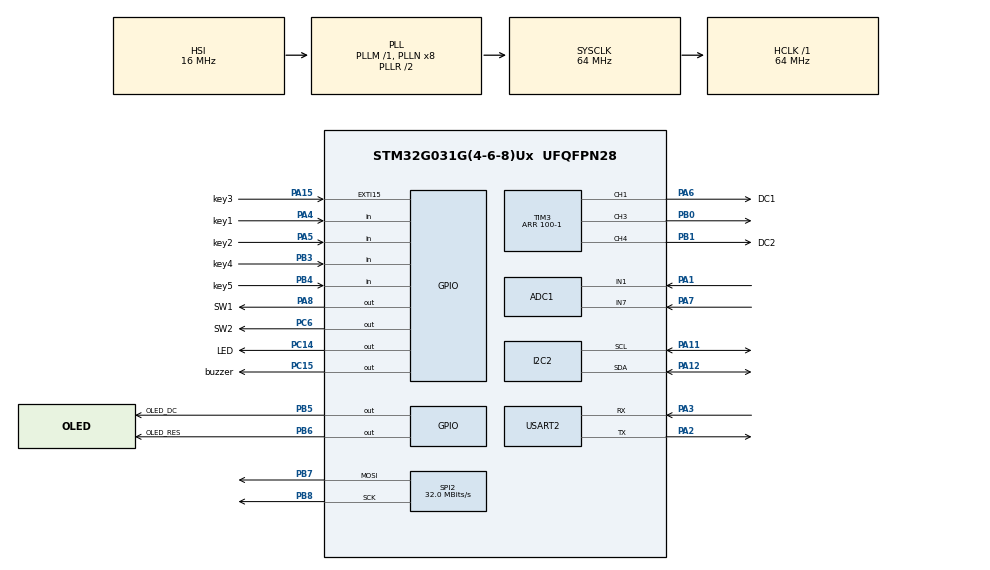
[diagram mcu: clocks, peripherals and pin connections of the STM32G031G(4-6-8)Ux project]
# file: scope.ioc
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ADC1.Channel-0\#ChannelRegularConversion=ADC_CHANNEL_1
ADC1.Channel-3\#ChannelRegularConversion=ADC_CHANNEL_7
ADC1.Channel-4\#ChannelRegularConversion=ADC_CHANNEL_VREFINT
ADC1.ClockPrescaler=ADC_CLOCK_SYNC_PCLK_DIV2
ADC1.ContinuousConvMode=DISABLE
ADC1.DMAContinuousRequests=ENABLE
ADC1.EOCSelection=ADC_EOC_SEQ_CONV
ADC1.ExternalTrigConv=ADC_EXTERNALTRIG_T2_TRGO
ADC1.NbrOfConversion=3
ADC1.NbrOfConversionFlag=1
ADC1.Overrun=ADC_OVR_DATA_OVERWRITTEN
ADC1.Rank-3\#ChannelRegularConversion=2
ADC1.Rank-4\#ChannelRegularConversion=3
ADC1.SamplingTime-3\#ChannelRegularConversion=ADC_SAMPLINGTIME_COMMON_1
ADC1.SamplingTime-4\#ChannelRegularConversion=ADC_SAMPLINGTIME_COMMON_2
ADC1.SamplingTimeCommon1=ADC_SAMPLETIME_1CYCLE_5
ADC1.SamplingTimeCommon2=ADC_SAMPLETIME_1CYCLE_5
ADC1.SelectedChannel=ADC_CHANNEL_1|ADC_CHANNEL_7|ADC_CHANNEL_VREFINT
ADC1.master=1
Dma.ADC1.2.Direction=DMA_PERIPH_TO_MEMORY
Dma.ADC1.2.EventEnable=DISABLE
Dma.ADC1.2.Instance=DMA1_Channel1
Dma.ADC1.2.MemDataAlignment=DMA_MDATAALIGN_HALFWORD
Dma.ADC1.2.MemInc=DMA_MINC_ENABLE
Dma.ADC1.2.Mode=DMA_CIRCULAR
Dma.ADC1.2.PeriphDataAlignment=DMA_PDATAALIGN_HALFWORD
Dma.ADC1.2.PeriphInc=DMA_PINC_DISABLE
Dma.ADC1.2.Polarity=HAL_DMAMUX_REQ_GEN_RISING
Dma.ADC1.2.Priority=DMA_PRIORITY_LOW
Dma.ADC1.2.RequestNumber=1
Dma.ADC1.2.SignalID=NONE
Dma.ADC1.2.SyncEnable=DISABLE
Dma.ADC1.2.SyncPolarity=HAL_DMAMUX_SYNC_NO_EVENT
Dma.ADC1.2.SyncRequestNumber=1
Dma.ADC1.2.SyncSignalID=NONE
Dma.Request0=USART2_RX
Dma.Request1=USART2_TX
Dma.Request2=ADC1
Dma.USART2_RX.0.Direction=DMA_PERIPH_TO_MEMORY
Dma.USART2_RX.0.EventEnable=DISABLE
Dma.USART2_RX.0.Instance=DMA1_Channel2
Dma.USART2_RX.0.MemDataAlignment=DMA_MDATAALIGN_BYTE
Dma.USART2_RX.0.MemInc=DMA_MINC_ENABLE
Dma.USART2_RX.0.Mode=DMA_CIRCULAR
Dma.USART2_RX.0.PeriphDataAlignment=DMA_PDATAALIGN_BYTE
Dma.USART2_RX.0.PeriphInc=DMA_PINC_DISABLE
Dma.USART2_RX.0.Polarity=HAL_DMAMUX_REQ_GEN_RISING
Dma.USART2_RX.0.Priority=DMA_PRIORITY_LOW
Dma.USART2_RX.0.RequestNumber=1
Dma.USART2_RX.0.SignalID=NONE
Dma.USART2_RX.0.SyncEnable=DISABLE
Dma.USART2_RX.0.SyncPolarity=HAL_DMAMUX_SYNC_NO_EVENT
Dma.USART2_RX.0.SyncRequestNumber=1
Dma.USART2_RX.0.SyncSignalID=NONE
Dma.USART2_TX.1.Direction=DMA_MEMORY_TO_PERIPH
Dma.USART2_TX.1.EventEnable=DISABLE
Dma.USART2_TX.1.Instance=DMA1_Channel3
Dma.USART2_TX.1.MemDataAlignment=DMA_MDATAALIGN_BYTE
Dma.USART2_TX.1.MemInc=DMA_MINC_ENABLE
Dma.USART2_TX.1.Mode=DMA_CIRCULAR
Dma.USART2_TX.1.PeriphDataAlignment=DMA_PDATAALIGN_BYTE
Dma.USART2_TX.1.PeriphInc=DMA_PINC_DISABLE
Dma.USART2_TX.1.Polarity=HAL_DMAMUX_REQ_GEN_RISING
Dma.USART2_TX.1.Priority=DMA_PRIORITY_LOW
Dma.USART2_TX.1.RequestNumber=1
Dma.USART2_TX.1.SignalID=NONE
Dma.USART2_TX.1.SyncEnable=DISABLE
Dma.USART2_TX.1.SyncPolarity=HAL_DMAMUX_SYNC_NO_EVENT
Dma.USART2_TX.1.SyncRequestNumber=1
Dma.USART2_TX.1.SyncSignalID=NONE
I2C2.Timing=0x10B17DB5
Mcu.Family=STM32G0
Mcu.Name=STM32G031G(4-6-8)Ux
Mcu.Package=UFQFPN28
NVIC.ADC1_IRQn=true\:1\:0\:true\:false\:true\:true\:true\:true
NVIC.DMA1_Channel1_IRQn=true\:1\:0\:true\:false\:true\:false\:true\:true
NVIC.DMA1_Channel2_3_IRQn=true\:1\:0\:true\:false\:true\:false\:true\:true
NVIC.EXTI4_15_IRQn=true\:0\:0\:false\:false\:true\:true\:true\:true
NVIC.I2C2_IRQn=true\:1\:0\:true\:false\:true\:true\:true\:true
NVIC.TIM17_IRQn=true\:0\:0\:true\:false\:true\:true\:true\:true
NVIC.TIM3_IRQn=true\:0\:0\:false\:false\:true\:true\:true\:true
PA1.Mode=IN1
PA1.Signal=ADC1_IN1
PA11\ [PA9].Mode=I2C
PA11\ [PA9].Signal=I2C2_SCL
PA12\ [PA10].Mode=I2C
PA12\ [PA10].Signal=I2C2_SDA
PA13.Mode=Serial_Wire
PA13.Signal=SYS_SWDIO
PA14-BOOT0.Mode=Serial_Wire
PA14-BOOT0.Signal=SYS_SWCLK
PA15.GPIO_Label=key3
PA15.GPIO_ModeDefaultEXTI=GPIO_MODE_IT_RISING_FALLING
PA15.Signal=GPXTI15
PA2.Mode=Asynchronous
PA2.Signal=USART2_TX
PA3.Mode=Asynchronous
PA3.Signal=USART2_RX
PA4.GPIO_Label=key1
PA4.Signal=GPIO_Input
PA5.GPIO_Label=key2
PA5.Signal=GPIO_Input
PA6.GPIO_Label=DC1
PA6.Signal=S_TIM3_CH1
PA7.Mode=IN7
PA7.Signal=ADC1_IN7
PA8.GPIO_Label=SW1
PA8.PinState=GPIO_PIN_SET
PA8.Signal=GPIO_Output
PB0.Signal=S_TIM3_CH3
PB1.GPIO_Label=DC2
PB1.Signal=S_TIM3_CH4
PB3.GPIO_Label=key4
PB3.Signal=GPIO_Input
PB4.GPIO_Label=key5
PB4.Signal=GPIO_Input
PB5.GPIO_Label=OLED_DC
PB5.GPIO_Speed=GPIO_SPEED_FREQ_HIGH
PB5.Signal=GPIO_Output
PB6.GPIO_Label=OLED_RES
PB6.GPIO_Speed=GPIO_SPEED_FREQ_HIGH
PB6.PinState=GPIO_PIN_RESET
PB6.Signal=GPIO_Output
PB7.GPIO_FM7=SYSCFG_FASTMODEPLUS_PB7
PB7.GPIO_Speed=GPIO_SPEED_FREQ_HIGH
PB7.Mode=TX_Only_Simplex_Unidirect_Master
PB7.Signal=SPI2_MOSI
PB8.GPIO_FM8=SYSCFG_FASTMODEPLUS_PB8
PB8.GPIO_Speed=GPIO_SPEED_FREQ_HIGH
PB8.Mode=TX_Only_Simplex_Unidirect_Master
PB8.Signal=SPI2_SCK
PC14-OSC32_IN\ (PC14).GPIO_Label=LED
PC14-OSC32_IN\ (PC14).Signal=GPIO_Output
PC15-OSC32_OUT\ (PC15).GPIO_Label=buzzer
PC15-OSC32_OUT\ (PC15).Signal=GPIO_Output
PC6.GPIO_Label=SW2
PC6.PinState=GPIO_PIN_SET
PC6.Signal=GPIO_Output
ProjectManager.HeapSize=0x200
ProjectManager.StackSize=0x400
ProjectManager.TargetToolchain=MDK-ARM V5.32
RCC.ADCFreq_Value=64000000
RCC.AHBFreq_Value=64000000
RCC.CortexFreq_Value=64000000
RCC.EXTERNAL_CLOCK_VALUE=12288000
RCC.HCLKFreq_Value=64000000
RCC.HSE_VALUE=8000000
RCC.HSI_VALUE=16000000
RCC.LSE_VALUE=32768
RCC.PLLQ=RCC_PLLQ_DIV4
RCC.SYSCLKFreq_VALUE=64000000
RCC.SYSCLKSource=RCC_SYSCLKSOURCE_PLLCLK
RCC.VCOOutputFreq_Value=128000000
SH.S_TIM3_CH1.0=TIM3_CH1,PWM Generation1 CH1
SH.S_TIM3_CH3.0=TIM3_CH3,PWM Generation3 CH3
SH.S_TIM3_CH4.0=TIM3_CH4,PWM Generation4 CH4
SPI2.CLKPolarity=SPI_POLARITY_HIGH
SPI2.CalculateBaudRate=32.0 MBits/s
SPI2.Direction=SPI_DIRECTION_2LINES
SPI2.Mode=SPI_MODE_MASTER
SPI2.VirtualType=VM_MASTER
TIM17.AutoReloadPreload=TIM_AUTORELOAD_PRELOAD_ENABLE
TIM17.Period=10-1
TIM17.Prescaler=6400-1
TIM2.AutoReloadPreload=TIM_AUTORELOAD_PRELOAD_ENABLE
TIM2.Channel-Output\ Compare2\ No\ Output=TIM_CHANNEL_2
TIM2.Period=100-1
TIM2.Pulse-Output\ Compare2\ No\ Output=50-1
TIM2.TIM_MasterOutputTrigger=TIM_TRGO_UPDATE
TIM2.TIM_MasterSlaveMode=TIM_MASTERSLAVEMODE_ENABLE
TIM3.AutoReloadPreload=TIM_AUTORELOAD_PRELOAD_DISABLE
TIM3.Channel-PWM\ Generation1\ CH1=TIM_CHANNEL_1
TIM3.Channel-PWM\ Generation3\ CH3=TIM_CHANNEL_3
TIM3.Channel-PWM\ Generation4\ CH4=TIM_CHANNEL_4
TIM3.OCFastMode_PWM-PWM\ Generation1\ CH1=TIM_OCFAST_ENABLE
TIM3.OCFastMode_PWM-PWM\ Generation4\ CH4=TIM_OCFAST_ENABLE
TIM3.Period=100-1
TIM3.Pulse-PWM\ Generation1\ CH1=50
TIM3.Pulse-PWM\ Generation3\ CH3=50
TIM3.Pulse-PWM\ Generation4\ CH4=50
USART2.VirtualMode-Asynchronous=VM_ASYNC
VP_ADC1_Vref_Input.Mode=IN-Vrefint
VP_TIM17_VS_ClockSourceINT.Mode=Enable_Timer
VP_TIM2_VS_ClockSourceINT.Mode=Internal
VP_TIM2_VS_no_output2.Mode=Output Compare2 No Output
VP_TIM3_VS_ClockSourceINT.Mode=Internal
board=custom

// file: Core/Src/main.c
/* USER CODE BEGIN Header */
/**
  ******************************************************************************
  * @file           : main.c
  * @brief          : Main program body
  * @author         : Max-unterwegs
  * @date           : 2025-03-07 20:07:21
  * @note           : scope主函数，完整工程见https://github.com/Max-unterwegs/scope-von-Max_unterwegs
  ******************************************************************************
  * @attention
  *
  * Copyright (c) 2025 STMicroelectronics.
  * All rights reserved.
  *
  * This software is licensed under terms that can be found in the LICENSE file
  * in the root directory of this software component.
  * If no LICENSE file comes with this software, it is provided AS-IS.
  *
  ******************************************************************************
  */
/*
 *                        _oo0oo_
 *                       o8888888o
 *                       88" . "88
 *                       (| -_- |)
 *                       0\  =  /0
 *                     ___/`---'\___
 *                   .' \\|     |// '.
 *                  / \\|||  :  |||// \
 *                 / _||||| -:- |||||- \
 *                |   | \\\  - /// |   |
 *                | \_|  ''\---/''  |_/ |
 *                \  .-\__  '-'  ___/-. /
 *              ___'. .'  /--.--\  `. .'___
 *           ."" '<  `.___\_<|>_/___.' >' "".
 *          | | :  `- \`.;`\ _ /`;.`/ - ` : | |
 *          \  \ `_.   \_ __\ /__ _/   .-` /  /
 *      =====`-.____`.___ \_____/___.-`___.-'=====
 *                        `=---='
 *
 *
 *      ~~~~~~~~~~~~~~~~~~~~~~~~~~~~~~~~~~~~~~~~~~~
 *
 *            佛祖保佑     永不宕机     永无BUG
 */

/* USER CODE END Header */
#include "main.h"
#include "adc.h"
#include "dma.h"
#include "i2c.h"
#include "spi.h"
#include "tim.h"
#include "usart.h"
#include "gpio.h"

/* USER CODE BEGIN Includes */
#include "status.h"
#include "printf.h"
#include "show.h"
/* USER CODE END Includes */

void SystemClock_Config(void);

int main(void)
{

  /* MCU Configuration--------------------------------------------------------*/

  /* Reset of all peripherals, Initializes the Flash interface and the Systick. */
  HAL_Init();

  /* Configure the system clock */
  SystemClock_Config();

  /* Initialize all configured peripherals */
  MX_GPIO_Init();
  MX_DMA_Init();
  MX_ADC1_Init();
  MX_I2C2_Init();
  MX_SPI2_Init();
  MX_USART2_UART_Init();
  MX_TIM2_Init();
  MX_TIM3_Init();
  MX_TIM17_Init();
  /* USER CODE BEGIN 2 */
  HAL_TIM_Base_Start_IT(&htim17);
  showinit();
  init_status();
  /* USER CODE END 2 */

  /* Infinite loop */
  /* USER CODE BEGIN WHILE */
  while (1)
  {
    main_status();
    /* USER CODE END WHILE */

  }
}

void SystemClock_Config(void)
{
  RCC_OscInitTypeDef RCC_OscInitStruct = {0};
  RCC_ClkInitTypeDef RCC_ClkInitStruct = {0};

  /** Configure the main internal regulator output voltage
  */
  HAL_PWREx_ControlVoltageScaling(PWR_REGULATOR_VOLTAGE_SCALE1);

  /** Initializes the RCC Oscillators according to the specified parameters
  * in the RCC_OscInitTypeDef structure.
  */
  RCC_OscInitStruct.OscillatorType = RCC_OSCILLATORTYPE_HSI;
  RCC_OscInitStruct.HSIState = RCC_HSI_ON;
  RCC_OscInitStruct.HSIDiv = RCC_HSI_DIV1;
  RCC_OscInitStruct.HSICalibrationValue = RCC_HSICALIBRATION_DEFAULT;
  RCC_OscInitStruct.PLL.PLLState = RCC_PLL_ON;
  RCC_OscInitStruct.PLL.PLLSource = RCC_PLLSOURCE_HSI;
  RCC_OscInitStruct.PLL.PLLM = RCC_PLLM_DIV1;
  RCC_OscInitStruct.PLL.PLLN = 8;
  RCC_OscInitStruct.PLL.PLLP = RCC_PLLP_DIV2;
  RCC_OscInitStruct.PLL.PLLQ = RCC_PLLQ_DIV4;
  RCC_OscInitStruct.PLL.PLLR = RCC_PLLR_DIV2;
  if (HAL_RCC_OscConfig(&RCC_OscInitStruct) != HAL_OK)
  {
    Error_Handler();
  }

  /** Initializes the CPU, AHB and APB buses clocks
  */
  RCC_ClkInitStruct.ClockType = RCC_CLOCKTYPE_HCLK|RCC_CLOCKTYPE_SYSCLK
                              |RCC_CLOCKTYPE_PCLK1;
  RCC_ClkInitStruct.SYSCLKSource = RCC_SYSCLKSOURCE_PLLCLK;
  RCC_ClkInitStruct.AHBCLKDivider = RCC_SYSCLK_DIV1;
  RCC_ClkInitStruct.APB1CLKDivider = RCC_HCLK_DIV1;

  if (HAL_RCC_ClockConfig(&RCC_ClkInitStruct, FLASH_LATENCY_2) != HAL_OK)
  {
    Error_Handler();
  }
}

void Error_Handler(void)
{
  /* USER CODE BEGIN Error_Handler_Debug */
  /* User can add his own implementation to report the HAL error return state */
  __disable_irq();
  while (1)
  {
    printf("error\r\n");
  }
  /* USER CODE END Error_Handler_Debug */
}
